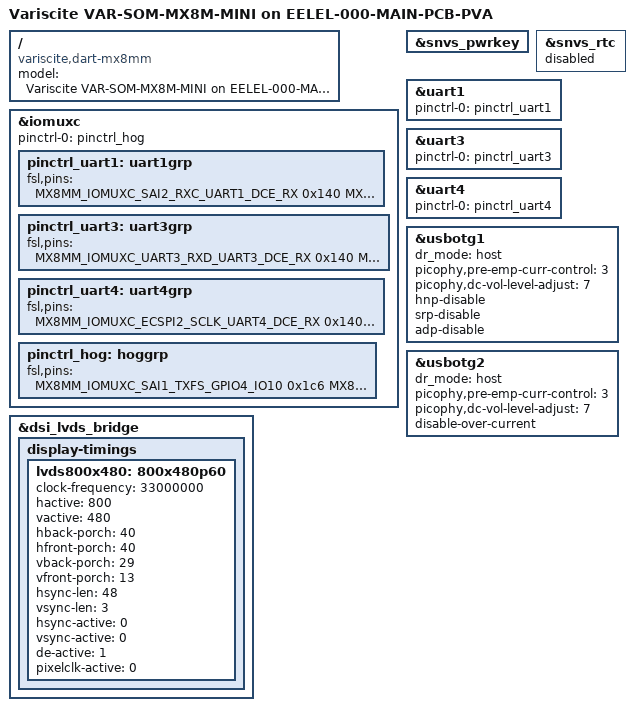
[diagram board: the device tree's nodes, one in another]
// SPDX-License-Identifier: (GPL-2.0+ OR MIT)
/*
 * Copyright 2019 NXP
 * Copyright 2019-2022 Variscite Ltd.
 * Copyright 2022-2023 Mosaic Manufacturing Ltd.
 */

/dts-v1/;

#include <dt-bindings/usb/pd.h>
#include "imx8mm-var-som.dtsi"

/ {
  model = "Variscite VAR-SOM-MX8M-MINI on EELEL-000-MAIN-PCB-PVA";
  compatible = "variscite,dart-mx8mm", "fsl,imx8mm";
};

&iomuxc {
    pinctrl-names = "default";
    pinctrl-0 = <&pinctrl_hog>;

  pinctrl_uart1: uart1grp {
    fsl,pins = <
      MX8MM_IOMUXC_SAI2_RXC_UART1_DCE_RX      0x140
      MX8MM_IOMUXC_SAI2_RXFS_UART1_DCE_TX     0x140
    >;
  };

  pinctrl_uart3: uart3grp {
    fsl,pins = <
      MX8MM_IOMUXC_UART3_RXD_UART3_DCE_RX     0x140
      MX8MM_IOMUXC_UART3_TXD_UART3_DCE_TX     0x140
    >;
  };

  pinctrl_uart4: uart4grp {
    fsl,pins = <
      MX8MM_IOMUXC_ECSPI2_SCLK_UART4_DCE_RX   0x140
      MX8MM_IOMUXC_ECSPI2_MOSI_UART4_DCE_TX   0x140
    >;
  };

  pinctrl_hog: hoggrp {
    fsl,pins = <
      MX8MM_IOMUXC_SAI1_TXFS_GPIO4_IO10       0x1c6
      MX8MM_IOMUXC_GPIO1_IO15_GPIO1_IO15      0x1c6
      MX8MM_IOMUXC_SAI3_TXD_GPIO5_IO1         0x1c6
      MX8MM_IOMUXC_GPIO1_IO06_GPIO1_IO6       0x1c6
      MX8MM_IOMUXC_SAI2_TXD0_GPIO4_IO26       0x1c6
      MX8MM_IOMUXC_GPIO1_IO07_GPIO1_IO7       0x1c6
      MX8MM_IOMUXC_ECSPI1_MISO_GPIO5_IO8      0x1c6
      MX8MM_IOMUXC_SAI5_MCLK_GPIO3_IO25       0x1c6
      MX8MM_IOMUXC_SAI2_TXFS_GPIO4_IO24       0x1c6
      MX8MM_IOMUXC_SD2_CLK_GPIO2_IO13         0x1c6
    >;
  };
};

&snvs_pwrkey {
  status = "okay";
};

&snvs_rtc {
  status = "disabled";
};

&uart1 {
  pinctrl-names = "default";
  pinctrl-0 = <&pinctrl_uart1>;
  status = "okay";
};

&uart3 {
  pinctrl-names = "default";
  pinctrl-0 = <&pinctrl_uart3>;
  status = "okay";
};

&uart4 {
  pinctrl-names = "default";
  pinctrl-0 = <&pinctrl_uart4>;
  status = "okay";
};

&usbotg1 {
  dr_mode = "host";
  picophy,pre-emp-curr-control = <3>;
  picophy,dc-vol-level-adjust = <7>;
  hnp-disable;
  srp-disable;
  adp-disable;
  status = "okay";
};

&usbotg2 {
  dr_mode = "host";
  picophy,pre-emp-curr-control = <3>;
  picophy,dc-vol-level-adjust = <7>;
  disable-over-current;
  status = "okay";
};

&dsi_lvds_bridge {
  display-timings {
       lvds800x480: 800x480p60 {
      clock-frequency = <33000000>;
      hactive = <800>;
      vactive = <480>;
      hback-porch = <40>;
      hfront-porch = <40>;
      vback-porch = <29>;
      vfront-porch = <13>;
      hsync-len = <48>;
      vsync-len = <3>;
      hsync-active = <0>;
      vsync-active = <0>;
      de-active = <1>;
      pixelclk-active = <0>;
    }; 
  };
};
